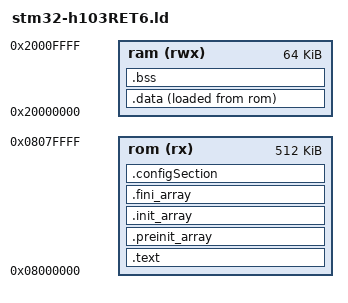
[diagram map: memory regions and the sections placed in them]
/* Linker script for the Battery Management System

This script is an adaptation of the script used in libopencm3 to define all
sections independently of libopencm3 and to introduce a section of FLASH
to store configuration data. */

/*
 * This file is part of the libopencm3 project.
 *
 * Copyright (C) 2009 Uwe Hermann <uwe@hermann-uwe.de>
 * Copyright (C) 2014 K. Sarkies
 *
 * This program is free software: you can redistribute it and/or modify
 * it under the terms of the GNU General Public License as published by
 * the Free Software Foundation, either version 3 of the License, or
 * (at your option) any later version.
 *
 * This program is distributed in the hope that it will be useful,
 * but WITHOUT ANY WARRANTY; without even the implied warranty of
 * MERCHANTABILITY or FITNESS FOR A PARTICULAR PURPOSE.  See the
 * GNU General Public License for more details.
 *
 * You should have received a copy of the GNU General Public License
 * along with this program.  If not, see <http://www.gnu.org/licenses/>.
 */

/* Linker script STM32F103RET6, 512K flash, 64K RAM. */

/* Define memory regions. */
MEMORY
{
	rom (rx) : ORIGIN = 0x08000000, LENGTH = 512K
	ram (rwx) : ORIGIN = 0x20000000, LENGTH = 64K
}

/* Enforce emission of the vector table. */
EXTERN (vector_table)

/* Define the entry point of the output file. */
ENTRY(reset_handler)

/* Define sections. */
SECTIONS
{
	.text : {
		*(.vectors)	/* Vector table */
		*(.text*)	/* Program code */
		. = ALIGN(4);
		*(.rodata*)	/* Read-only data */
		. = ALIGN(4);
	} >rom

	/* C++ Static constructors/destructors, also used for __attribute__
	 * ((constructor)) and the likes */
	.preinit_array : {
		. = ALIGN(4);
		__preinit_array_start = .;
		KEEP (*(.preinit_array))
		__preinit_array_end = .;
	} >rom
	.init_array : {
		. = ALIGN(4);
		__init_array_start = .;
		KEEP (*(SORT(.init_array.*)))
		KEEP (*(.init_array))
		__init_array_end = .;
	} >rom
	.fini_array : {
		. = ALIGN(4);
		__fini_array_start = .;
		KEEP (*(.fini_array))
		KEEP (*(SORT(.fini_array.*)))
		__fini_array_end = .;
	} >rom

	.data : {
		_data = .;
		*(.data*)	/* Read-write initialized data */
		_edata = .;
	} >ram AT >rom
	_data_loadaddr = LOADADDR(.data);

/* This is a section set aside for configuration data in FLASH.
Align at a page boundary and allocate to input section .configBlock
which appears in power-management-objdic.c
Place a bit pattern at the start for testing. */
	.configSection : {
		. = ALIGN(2048);
        __configBlockStart = .;
        *(.configBlock)  /* configuration data block */
        __configBlockEnd = .;
	} >rom

	.bss : {
		*(.bss*)	/* Read-write zero initialized data */
		*(COMMON)
		. = ALIGN(4);
		_ebss = .;
	} >ram
	end = .;
}

PROVIDE(_stack = ORIGIN(ram) + LENGTH(ram));

